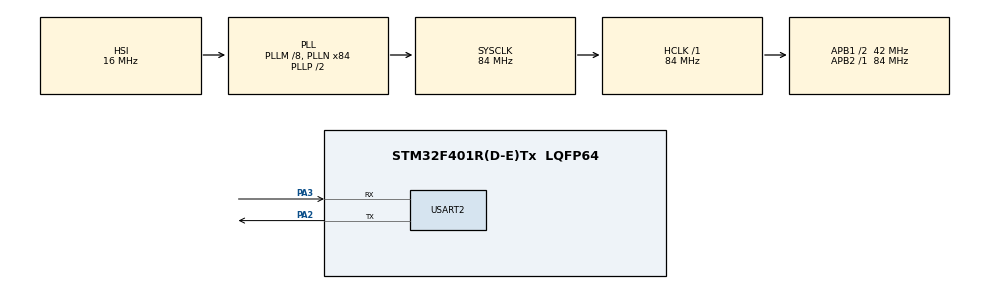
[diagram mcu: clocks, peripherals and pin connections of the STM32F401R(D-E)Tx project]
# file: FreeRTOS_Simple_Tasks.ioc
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FREERTOS.Tasks01=defaultTask,0,128,StartDefaultTask,Default,NULL,Dynamic,NULL,NULL;myTask02,-3,128,StartTask02,Default,NULL,Dynamic,NULL,NULL;myTask03,-3,128,StartTask03,Default,NULL,Dynamic,NULL,NULL
Mcu.Family=STM32F4
Mcu.Name=STM32F401R(D-E)Tx
Mcu.Package=LQFP64
NVIC.PriorityGroup=NVIC_PRIORITYGROUP_4
NVIC.TIM1_UP_TIM10_IRQn=true\:0\:0\:false\:false\:true\:false\:false\:true
NVIC.TimeBase=TIM1_UP_TIM10_IRQn
NVIC.TimeBaseIP=TIM1
PA13.Mode=Serial_Wire
PA13.Signal=SYS_JTMS-SWDIO
PA14.Mode=Serial_Wire
PA14.Signal=SYS_JTCK-SWCLK
PA2.Mode=Asynchronous
PA2.Signal=USART2_TX
PA3.Mode=Asynchronous
PA3.Signal=USART2_RX
PH0\ -\ OSC_IN.Mode=HSE-External-Clock-Source
PH0\ -\ OSC_IN.Signal=RCC_OSC_IN
PH1\ -\ OSC_OUT.Mode=HSE-External-Clock-Source
PH1\ -\ OSC_OUT.Signal=RCC_OSC_OUT
ProjectManager.HeapSize=0x200
ProjectManager.StackSize=0x400
ProjectManager.TargetToolchain=STM32CubeIDE
RCC.48MHZClocksFreq_Value=42000000
RCC.AHBFreq_Value=84000000
RCC.APB1CLKDivider=RCC_HCLK_DIV2
RCC.APB1Freq_Value=42000000
RCC.APB1TimFreq_Value=84000000
RCC.APB2Freq_Value=84000000
RCC.APB2TimFreq_Value=84000000
RCC.CortexFreq_Value=84000000
RCC.HCLKFreq_Value=84000000
RCC.HSE_VALUE=8000000
RCC.HSI_VALUE=16000000
RCC.LSE_VALUE=32768
RCC.PLLM=8
RCC.PLLN=84
RCC.SYSCLKFreq_VALUE=84000000
RCC.SYSCLKSource=RCC_SYSCLKSOURCE_PLLCLK
RCC.VCOOutputFreq_Value=168000000
USART2.VirtualMode=VM_ASYNC
VP_FREERTOS_VS_CMSIS_V1.Mode=CMSIS_V1
VP_SYS_VS_tim1.Mode=TIM1
board=custom

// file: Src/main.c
/* USER CODE BEGIN Header */
/**
  ******************************************************************************
  * @file           : main.c
  * @brief          : Main program body
  ******************************************************************************
  * @attention
  *
  * <h2><center>&copy; Copyright (c) 2021 STMicroelectronics.
  * All rights reserved.</center></h2>
  *
  * This software component is licensed by ST under Ultimate Liberty license
  * SLA0044, the "License"; You may not use this file except in compliance with
  * the License. You may obtain a copy of the License at:
  *                             www.st.com/SLA0044
  *
  ******************************************************************************
  */
/* USER CODE END Header */
#include "main.h"
#include "cmsis_os.h"

UART_HandleTypeDef huart2;

osThreadId defaultTaskHandle;
osThreadId myTask02Handle;
osThreadId myTask03Handle;

void SystemClock_Config(void);
static void MX_GPIO_Init(void);
static void MX_USART2_UART_Init(void);
void StartDefaultTask(void const * argument);
void StartTask02(void const * argument);
void StartTask03(void const * argument);

/* USER CODE BEGIN 0 */
void transmit_def (void)
{
	uint8_t data[] = "Hello DEFTASK\n";
	HAL_UART_Transmit(&huart2, data, 14, 1000);
}

void transmit_task2 (void)
{
	uint8_t data[] = "Hello TASK2\n";
	HAL_UART_Transmit(&huart2, data, 12, 1000);
}

void transmit_task3 (void)
{
	uint8_t data[] = "Hello TASK3\n";
	HAL_UART_Transmit(&huart2, data, 12, 1000);

}

/* USER CODE END 0 */

int main(void)
{

  /* MCU Configuration--------------------------------------------------------*/

  /* Reset of all peripherals, Initializes the Flash interface and the Systick. */
  HAL_Init();

  /* Configure the system clock */
  SystemClock_Config();

  /* Initialize all configured peripherals */
  MX_GPIO_Init();
  MX_USART2_UART_Init();

  /* Create the thread(s) */
  /* definition and creation of defaultTask */
  osThreadDef(defaultTask, StartDefaultTask, osPriorityNormal, 0, 128);
  defaultTaskHandle = osThreadCreate(osThread(defaultTask), NULL);

  /* definition and creation of myTask02 */
  osThreadDef(myTask02, StartTask02, osPriorityIdle, 0, 128);
  myTask02Handle = osThreadCreate(osThread(myTask02), NULL);

  /* definition and creation of myTask03 */
  osThreadDef(myTask03, StartTask03, osPriorityIdle, 0, 128);
  myTask03Handle = osThreadCreate(osThread(myTask03), NULL);

  /* Start scheduler */
  osKernelStart();

  /* We should never get here as control is now taken by the scheduler */
  /* Infinite loop */
  while (1)
  {

  }
}

void SystemClock_Config(void)
{
  RCC_OscInitTypeDef RCC_OscInitStruct = {0};
  RCC_ClkInitTypeDef RCC_ClkInitStruct = {0};

  /** Configure the main internal regulator output voltage
  */
  __HAL_RCC_PWR_CLK_ENABLE();
  __HAL_PWR_VOLTAGESCALING_CONFIG(PWR_REGULATOR_VOLTAGE_SCALE2);
  /** Initializes the RCC Oscillators according to the specified parameters
  * in the RCC_OscInitTypeDef structure.
  */
  RCC_OscInitStruct.OscillatorType = RCC_OSCILLATORTYPE_HSI;
  RCC_OscInitStruct.HSIState = RCC_HSI_ON;
  RCC_OscInitStruct.HSICalibrationValue = RCC_HSICALIBRATION_DEFAULT;
  RCC_OscInitStruct.PLL.PLLState = RCC_PLL_ON;
  RCC_OscInitStruct.PLL.PLLSource = RCC_PLLSOURCE_HSI;
  RCC_OscInitStruct.PLL.PLLM = 8;
  RCC_OscInitStruct.PLL.PLLN = 84;
  RCC_OscInitStruct.PLL.PLLP = RCC_PLLP_DIV2;
  RCC_OscInitStruct.PLL.PLLQ = 4;
  if (HAL_RCC_OscConfig(&RCC_OscInitStruct) != HAL_OK)
  {
    Error_Handler();
  }
  /** Initializes the CPU, AHB and APB buses clocks
  */
  RCC_ClkInitStruct.ClockType = RCC_CLOCKTYPE_HCLK|RCC_CLOCKTYPE_SYSCLK
                              |RCC_CLOCKTYPE_PCLK1|RCC_CLOCKTYPE_PCLK2;
  RCC_ClkInitStruct.SYSCLKSource = RCC_SYSCLKSOURCE_PLLCLK;
  RCC_ClkInitStruct.AHBCLKDivider = RCC_SYSCLK_DIV1;
  RCC_ClkInitStruct.APB1CLKDivider = RCC_HCLK_DIV2;
  RCC_ClkInitStruct.APB2CLKDivider = RCC_HCLK_DIV1;

  if (HAL_RCC_ClockConfig(&RCC_ClkInitStruct, FLASH_LATENCY_2) != HAL_OK)
  {
    Error_Handler();
  }
}

static void MX_USART2_UART_Init(void)
{

  huart2.Instance = USART2;
  huart2.Init.BaudRate = 115200;
  huart2.Init.WordLength = UART_WORDLENGTH_8B;
  huart2.Init.StopBits = UART_STOPBITS_1;
  huart2.Init.Parity = UART_PARITY_NONE;
  huart2.Init.Mode = UART_MODE_TX_RX;
  huart2.Init.HwFlowCtl = UART_HWCONTROL_NONE;
  huart2.Init.OverSampling = UART_OVERSAMPLING_16;
  if (HAL_UART_Init(&huart2) != HAL_OK)
  {
    Error_Handler();
  }

}

static void MX_GPIO_Init(void)
{

  /* GPIO Ports Clock Enable */
  __HAL_RCC_GPIOH_CLK_ENABLE();
  __HAL_RCC_GPIOA_CLK_ENABLE();

}

void StartDefaultTask(void const * argument)
{
  /* USER CODE BEGIN 5 */
  /* Infinite loop */
  for(;;)
  {
	  transmit_def();
    osDelay(1);
  }
  /* USER CODE END 5 */
}

void StartTask02(void const * argument)
{
  /* USER CODE BEGIN StartTask02 */
  /* Infinite loop */
  for(;;)
  {
	  transmit_task2();
    osDelay(1);
  }
  /* USER CODE END StartTask02 */
}

void StartTask03(void const * argument)
{
  /* USER CODE BEGIN StartTask03 */
  /* Infinite loop */
  for(;;)
  {
   transmit_task3();
    osDelay(1);
  }
  /* USER CODE END StartTask03 */
}

 /**
  * @brief  Period elapsed callback in non blocking mode
  * @note   This function is called  when TIM1 interrupt took place, inside
  * HAL_TIM_IRQHandler(). It makes a direct call to HAL_IncTick() to increment
  * a global variable "uwTick" used as application time base.
  * @param  htim : TIM handle
  * @retval None
  */
void HAL_TIM_PeriodElapsedCallback(TIM_HandleTypeDef *htim)
{
  if (htim->Instance == TIM1) {
    HAL_IncTick();
  }
}

void Error_Handler(void)
{
  __disable_irq();
  while (1)
  {
  }
}

/************************ (C) COPYRIGHT STMicroelectronics *****END OF FILE****/

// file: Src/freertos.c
/* USER CODE BEGIN Header */
/**
  ******************************************************************************
  * File Name          : freertos.c
  * Description        : Code for freertos applications
  ******************************************************************************
  * @attention
  *
  * <h2><center>&copy; Copyright (c) 2021 STMicroelectronics.
  * All rights reserved.</center></h2>
  *
  * This software component is licensed by ST under Ultimate Liberty license
  * SLA0044, the "License"; You may not use this file except in compliance with
  * the License. You may obtain a copy of the License at:
  *                             www.st.com/SLA0044
  *
  ******************************************************************************
  */
/* USER CODE END Header */

#include "FreeRTOS.h"
#include "task.h"
#include "main.h"

/* GetIdleTaskMemory prototype (linked to static allocation support) */
void vApplicationGetIdleTaskMemory( StaticTask_t **ppxIdleTaskTCBBuffer, StackType_t **ppxIdleTaskStackBuffer, uint32_t *pulIdleTaskStackSize );

/* USER CODE BEGIN GET_IDLE_TASK_MEMORY */
static StaticTask_t xIdleTaskTCBBuffer;
static StackT ype_t xIdleStack[configMINIMAL_STACK_SIZE];

void vApplicationGetIdleTaskMemory( StaticTask_t **ppxIdleTaskTCBBuffer, StackType_t **ppxIdleTaskStackBuffer, uint32_t *pulIdleTaskStackSize )
{
  *ppxIdleTaskTCBBuffer = &xIdleTaskTCBBuffer;
  *ppxIdleTaskStackBuffer = &xIdleStack[0];
  *pulIdleTaskStackSize = configMINIMAL_STACK_SIZE;
  /* place for user code */
}
/* USER CODE END GET_IDLE_TASK_MEMORY */

/************************ (C) COPYRIGHT STMicroelectronics *****END OF FILE****/
